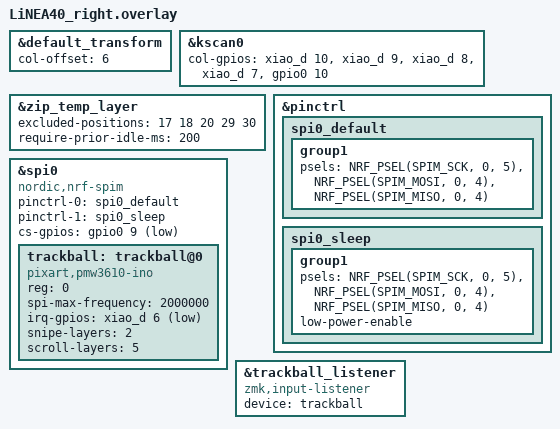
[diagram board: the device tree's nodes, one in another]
#include "LiNEA40.dtsi"
#include <dt-bindings/zmk/input_transform.h> // ← これが必要です
#include <input/processors.dtsi>        // 自分で追加したヘッダ
&default_transform {
    col-offset = <6>;
};

&kscan0 {
    col-gpios
        = <&xiao_d 10 GPIO_ACTIVE_HIGH> //col0-D10
        , <&xiao_d 9 GPIO_ACTIVE_HIGH>  //col1-D9
        , <&xiao_d 8 GPIO_ACTIVE_HIGH>  //col2-D8
        , <&xiao_d 7 GPIO_ACTIVE_HIGH>  //col3-D7
        , <&gpio0 10 GPIO_ACTIVE_HIGH>  //col4-NFC2
        ;
};

&zip_temp_layer {        // 下記のキーを押したらマウスモードを強制終了
    // 対象レイヤーはこのプロパティではなく、参照側の第1引数で決まる
    // (LiNEA40.keymapの <&zip_temp_layer MOUSE 10000> を参照)。
    // ここに書いた位置のキーは「押してもMOUSEレイヤーを解除しない」。
    // 逆に言うと、書いていないキーは押した瞬間にMOUSEレイヤーが落ちる。
    // MOUSEレイヤー上のキー(左右クリック等)は必ずここに入れること。
    excluded-positions = <
        //7  // I
        //16 // J
        17 // K … MOUSEレイヤーで&mkp MB1(左クリック)
        18 // L … MOUSEレイヤーで&mkp MB2(右クリック)
        //27   //,
        //28   //.
        20 // Z(shift)
        29 // /(shift)
        30 // Ctrl
    >;
    require-prior-idle-ms = <200>;    // キー入力中に誤ってトラックボールを触っても規定時間内はオートマウスレイヤー作動禁止
};

&pinctrl {
    spi0_default: spi0_default {
        group1 {
            psels = <NRF_PSEL(SPIM_SCK, 0, 5)>   // SCLK-D5
                  , <NRF_PSEL(SPIM_MOSI, 0, 4)>  // SDIO-D4
                  , <NRF_PSEL(SPIM_MISO, 0, 4)>  // SDIO-D4
                  ;
        };
    };

    spi0_sleep: spi0_sleep {
        group1 {
            psels = <NRF_PSEL(SPIM_SCK, 0, 5)>   // SCLK-D5
                  , <NRF_PSEL(SPIM_MOSI, 0, 4)>  // SDIO-D4
                  , <NRF_PSEL(SPIM_MISO, 0, 4)>  // SDIO-D4
                  ;
            low-power-enable;
        };
    };
};

&spi0 {
    status = "okay";
    compatible = "nordic,nrf-spim";
    pinctrl-0 = <&spi0_default>;
    pinctrl-1 = <&spi0_sleep>;
    pinctrl-names = "default", "sleep";
    cs-gpios = <&gpio0 9 GPIO_ACTIVE_LOW>; //NCS-NFC1

    trackball: trackball@0 {
        status = "okay";
        compatible = "pixart,pmw3610-ino";
        reg = <0>;
        spi-max-frequency = <2000000>;
        irq-gpios = <&xiao_d 6 (GPIO_ACTIVE_LOW | GPIO_PULL_UP)>; //MOT-D6
        snipe-layers = <2>;
        scroll-layers = <5>;
        //scroll-layers = <4 5 6>;
    };
};

&trackball_listener {
    status = "okay";
    compatible = "zmk,input-listener";
    device = <&trackball>;

    // input-processors と scroller は LiNEA40.keymap 側に集約している。
    // keymapはこのoverlayより後に適用され、同名プロパティを丸ごと上書きするため、
    // ここに書いても無視される(以前ここのzip_temp_layer指定が消えて左右クリックが
    // 効かなくなった)。変更する場合は LiNEA40.keymap の &trackball_listener を編集すること。
};
